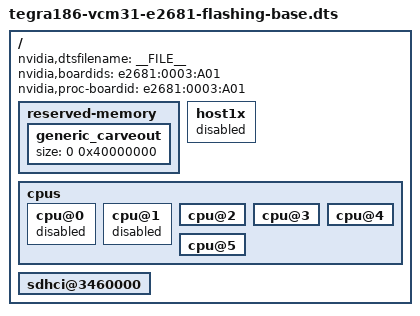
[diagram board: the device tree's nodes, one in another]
/*
 * tegra186-priv-vcm31-e2681-flashing-base.dts: E2681 flashing base dts
 *
 * Copyright (c) 2016, NVIDIA CORPORATION.  All rights reserved.
 *
 * This program is free software; you can redistribute it and/or modify
 * it under the terms of the GNU General Public License as published by
 * the Free Software Foundation; version 2 of the License.
 *
 * This program is distributed in the hope that it will be useful, but WITHOUT
 * ANY WARRANTY; without even the implied warranty of MERCHANTABILITY or
 * FITNESS FOR A PARTICULAR PURPOSE.  See the GNU General Public License for
 * more details.
 */

#include "tegra186-platforms/tegra186-vcm31-e2681-common.dtsi"
#include "t186-status-override/tegra186-vcm31-e2681-0003-a01-dt-status-override.dtsi"

/ {
	nvidia,dtsfilename = __FILE__;
	nvidia,boardids = "e2681:0003:A01";
	nvidia,proc-boardid = "e2681:0003:A01";

	reserved-memory {
		generic_carveout {
			status = "okay";
			size = <0 0x40000000>;
		};
	};
	host1x {
		status = "disabled";
	};

	cpus {
		cpu@0 {
			status = "disabled";
		};

		cpu@1 {
			status = "disabled";
		};

		cpu@2 {
			status = "okay";
		};

		cpu@3 {
			status = "okay";
		};

		cpu@4 {
			status = "okay";
		};

		cpu@5 {
			status = "okay";
		};
	};

	sdhci@3460000 {
		status = "okay";
	};
};
